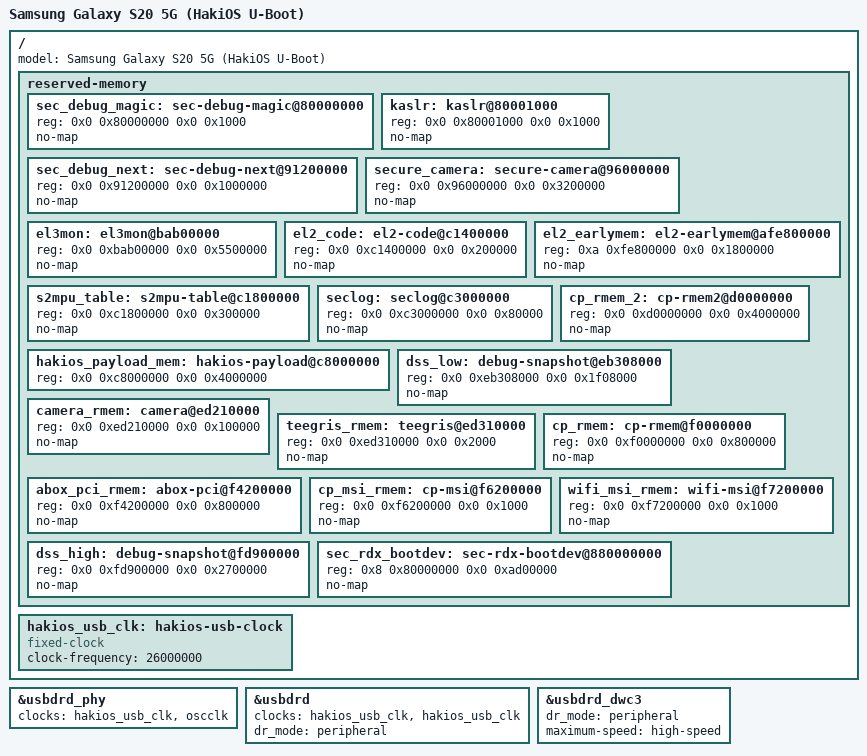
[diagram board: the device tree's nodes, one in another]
// SPDX-License-Identifier: GPL-2.0 OR BSD-3-Clause
/*
 * HakiOS's U-Boot on the Samsung Galaxy S20 5G (x1s, SM-G981B, Exynos 990).
 *
 * Linux's x1s device tree (dts/upstream: the framebuffer S-BOOT leaves on, the keys, USB), and what U-Boot and the
 * HakiOS loader must keep their hands off: every fixed carve-out of the phone's own Android device tree (the copy in
 * boot.img; only the addresses are written here, the file itself is Samsung's and stays off the repository) and the
 * 64 MiB where the hakios command puts the loader's payload. S-BOOT writes the RAM it found into the device tree it
 * hands over; the board code takes the banks from there, and the ones below only without it.
 *
 * The carve-outs Android's kernel allocates by size (ion, camera, abox-dbg, vts) are Linux's own and not here.
 */

/dts-v1/;
#include "exynos990-x1s.dts"

/ {
	model = "Samsung Galaxy S20 5G (HakiOS U-Boot)";

	reserved-memory {
		/* the firmware's (Samsung's tree: el3mon, sec_debug, secure_camera, s2mpu, seclog, teegris) */
		sec_debug_magic: sec-debug-magic@80000000 {
			reg = <0x0 0x80000000 0x0 0x1000>;
			no-map;
		};

		kaslr: kaslr@80001000 {
			reg = <0x0 0x80001000 0x0 0x1000>;
			no-map;
		};

		/* S-BOOT's next-boot debug area (bootargs sec_debug_next=0x1000000@0x91200000) */
		sec_debug_next: sec-debug-next@91200000 {
			reg = <0x0 0x91200000 0x0 0x1000000>;
			no-map;
		};

		secure_camera: secure-camera@96000000 {
			reg = <0x0 0x96000000 0x0 0x3200000>;
			no-map;
		};

		el3mon: el3mon@bab00000 {
			reg = <0x0 0xbab00000 0x0 0x5500000>;
			no-map;
		};

		/*
		 * Samsung's hypervisor (H-Arx, at EL2: U-Boot runs at EL1 under it). S-BOOT adds these to the tree it hands
		 * over; they are not in boot.img's. el2_earlymem is the top of the high bank: U-Boot must not move there.
		 */
		el2_code: el2-code@c1400000 {
			reg = <0x0 0xc1400000 0x0 0x200000>;
			no-map;
		};

		el2_earlymem: el2-earlymem@afe800000 {
			reg = <0xa 0xfe800000 0x0 0x1800000>;
			no-map;
		};

		s2mpu_table: s2mpu-table@c1800000 {
			reg = <0x0 0xc1800000 0x0 0x300000>;
			no-map;
		};

		seclog: seclog@c3000000 {
			reg = <0x0 0xc3000000 0x0 0x80000>;
			no-map;
		};

		/*
		 * The HakiOS loader's payload (cmd/hakios.c, CONFIG_HAKIOS_PAYLOAD_BASE; xnuloader/loader.c, the x1s
		 * platform). Qualcomm phones keep it at 0xF0000000, which here is the modem's and the framebuffer's.
		 * Mapped (no no-map): the hakios command writes the payload here, and nothing else in U-Boot may take it.
		 */
		hakios_payload_mem: hakios-payload@c8000000 {
			reg = <0x0 0xc8000000 0x0 0x4000000>;
		};

		/* the modem's (cp_rmem_2, cp_rmem, cp_msi) */
		cp_rmem_2: cp-rmem2@d0000000 {
			reg = <0x0 0xd0000000 0x0 0x4000000>;
			no-map;
		};

		/* debug-snapshot's logs S-BOOT reads back after a crash (log_pstore, log_s2d, log_arrdumppanic) */
		dss_low: debug-snapshot@eb308000 {
			reg = <0x0 0xeb308000 0x0 0x1f08000>;
			no-map;
		};

		camera_rmem: camera@ed210000 {
			reg = <0x0 0xed210000 0x0 0x100000>;
			no-map;
		};

		teegris_rmem: teegris@ed310000 {
			reg = <0x0 0xed310000 0x0 0x2000>;
			no-map;
		};

		cp_rmem: cp-rmem@f0000000 {
			reg = <0x0 0xf0000000 0x0 0x800000>;
			no-map;
		};

		/* audio (abox-pci-rmem; abox-rdma-compr and abox-rmem are Linux's audio@f7fb0000) */
		abox_pci_rmem: abox-pci@f4200000 {
			reg = <0x0 0xf4200000 0x0 0x800000>;
			no-map;
		};

		cp_msi_rmem: cp-msi@f6200000 {
			reg = <0x0 0xf6200000 0x0 0x1000>;
			no-map;
		};

		wifi_msi_rmem: wifi-msi@f7200000 {
			reg = <0x0 0xf7200000 0x0 0x1000>;
			no-map;
		};

		/* debug-snapshot's header and logs, 0xFD900000 to the end of the low 4 GiB */
		dss_high: debug-snapshot@fd900000 {
			reg = <0x0 0xfd900000 0x0 0x2700000>;
			no-map;
		};

		/* sec_rdx_bootdev, at the start of the high bank */
		sec_rdx_bootdev: sec-rdx-bootdev@880000000 {
			reg = <0x8 0x80000000 0x0 0xad00000>;
			no-map;
		};
	};
};

/*
 * USB: Linux takes its clocks from the Exynos990 clock driver, which U-Boot does not have yet. S-BOOT leaves the
 * USB block clocked (its own download mode uses it), so here they are fixed clocks that U-Boot only reads the rate of:
 * the PHY's reference is the 26 MHz oscillator. If the controller does not answer on the phone, this is the first suspect.
 */
/ {
	hakios_usb_clk: hakios-usb-clock {
		compatible = "fixed-clock";
		#clock-cells = <0>;
		clock-frequency = <26000000>;
	};
};

&usbdrd_phy {
	clocks = <&hakios_usb_clk>, <&oscclk>;
};

&usbdrd {
	clocks = <&hakios_usb_clk>, <&hakios_usb_clk>;
	dr_mode = "peripheral";
};

&usbdrd_dwc3 {
	dr_mode = "peripheral";
	maximum-speed = "high-speed";
};
